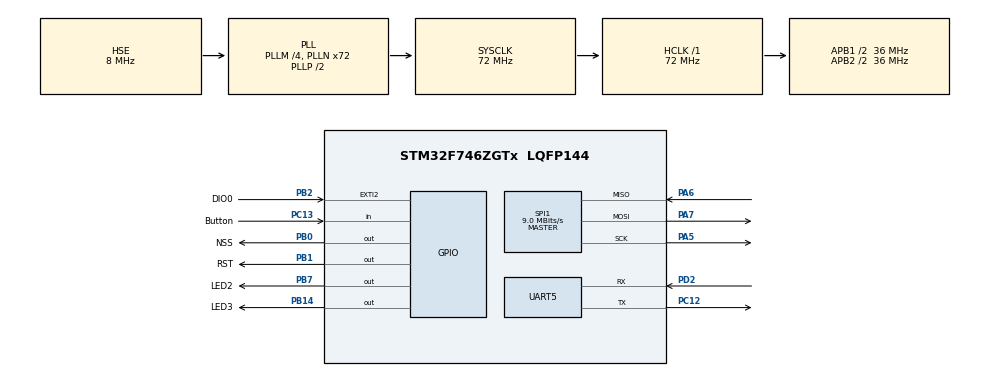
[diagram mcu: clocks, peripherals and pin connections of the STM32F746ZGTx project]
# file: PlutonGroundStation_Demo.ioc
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Mcu.Family=STM32F7
Mcu.Name=STM32F746ZGTx
Mcu.Package=LQFP144
NVIC.EXTI2_IRQn=true\:1\:1\:true\:false\:true\:true\:true\:true
NVIC.PriorityGroup=NVIC_PRIORITYGROUP_2
NVIC.UART5_IRQn=true\:1\:0\:true\:false\:true\:true\:true\:true
PA13.Mode=Serial_Wire
PA13.Signal=SYS_JTMS-SWDIO
PA14.Mode=Serial_Wire
PA14.Signal=SYS_JTCK-SWCLK
PA5.Mode=Full_Duplex_Master
PA5.Signal=SPI1_SCK
PA6.Mode=Full_Duplex_Master
PA6.Signal=SPI1_MISO
PA7.Mode=Full_Duplex_Master
PA7.Signal=SPI1_MOSI
PB0.GPIO_Label=NSS
PB0.PinState=GPIO_PIN_SET
PB0.Signal=GPIO_Output
PB1.GPIO_Label=RST
PB1.PinState=GPIO_PIN_SET
PB1.Signal=GPIO_Output
PB14.GPIO_Label=LED3
PB14.Signal=GPIO_Output
PB2.GPIO_Label=DIO0
PB2.Signal=GPXTI2
PB7.GPIO_Label=LED2
PB7.Signal=GPIO_Output
PC12.Mode=Asynchronous
PC12.Signal=UART5_TX
PC13.GPIO_Label=Button
PC13.Signal=GPIO_Input
PD2.Mode=Asynchronous
PD2.Signal=UART5_RX
PH0/OSC_IN.Mode=HSE-External-Oscillator
PH0/OSC_IN.Signal=RCC_OSC_IN
PH1/OSC_OUT.Mode=HSE-External-Oscillator
PH1/OSC_OUT.Signal=RCC_OSC_OUT
ProjectManager.HeapSize=0x200
ProjectManager.StackSize=0x400
ProjectManager.TargetToolchain=STM32CubeIDE
RCC.AHBFreq_Value=72000000
RCC.APB1CLKDivider=RCC_HCLK_DIV2
RCC.APB1Freq_Value=36000000
RCC.APB1TimFreq_Value=72000000
RCC.APB2CLKDivider=RCC_HCLK_DIV2
RCC.APB2Freq_Value=36000000
RCC.APB2TimFreq_Value=72000000
RCC.CortexFreq_Value=72000000
RCC.HCLKFreq_Value=72000000
RCC.HSE_VALUE=8000000
RCC.HSI_VALUE=16000000
RCC.LSE_VALUE=32768
RCC.PLLM=4
RCC.PLLN=72
RCC.PLLSourceVirtual=RCC_PLLSOURCE_HSE
RCC.SYSCLKFreq_VALUE=72000000
RCC.SYSCLKSource=RCC_SYSCLKSOURCE_PLLCLK
RCC.USBFreq_Value=72000000
RCC.VCOOutputFreq_Value=144000000
SPI1.BaudRatePrescaler=SPI_BAUDRATEPRESCALER_4
SPI1.CalculateBaudRate=9.0 MBits/s
SPI1.DataSize=SPI_DATASIZE_8BIT
SPI1.Direction=SPI_DIRECTION_2LINES
SPI1.Mode=SPI_MODE_MASTER
SPI1.VirtualType=VM_MASTER
board=custom

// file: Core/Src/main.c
/* USER CODE BEGIN Header */
/**
 ******************************************************************************
 * @file           : main.c
 * @brief          : Main program body
 ******************************************************************************
 * @attention
 *
 * Copyright (c) 2023 STMicroelectronics.
 * All rights reserved.
 *
 * This software is licensed under terms that can be found in the LICENSE file
 * in the root directory of this software component.
 * If no LICENSE file comes with this software, it is provided AS-IS.
 *
 ******************************************************************************
 */
/* USER CODE END Header */
#include "main.h"
#include "spi.h"
#include "usart.h"
#include "gpio.h"

/* USER CODE BEGIN Includes */
//#include "Main_App.h"
/* USER CODE END Includes */

void SystemClock_Config(void);

/* USER CODE BEGIN 0 */
void delay_ms(uint32_t ms) {
	uint32_t start = HAL_GetTick(); // Obtiene el tiempo inicial
	while ((HAL_GetTick() - start) < ms);
}
/* USER CODE END 0 */

int main(void)
{

  /* MCU Configuration--------------------------------------------------------*/

  /* Reset of all peripherals, Initializes the Flash interface and the Systick. */
  HAL_Init();

  /* Configure the system clock */
  SystemClock_Config();

  /* Initialize all configured peripherals */
  MX_GPIO_Init();
  MX_UART5_Init();
  MX_SPI1_Init();
  /* USER CODE BEGIN 2 */

	//------------MAIN APP INIT-----------------
	LoraApp_init();
	//------------------------------------------

  /* USER CODE END 2 */

  /* Infinite loop */
  /* USER CODE BEGIN WHILE */
	while (1)
	{
		//------------MAIN APP LOOP-----------------
		LoraApp_loopReceive();
		//------------------------------------------
    /* USER CODE END WHILE */

	}
}

void SystemClock_Config(void)
{
  RCC_OscInitTypeDef RCC_OscInitStruct = {0};
  RCC_ClkInitTypeDef RCC_ClkInitStruct = {0};

  /** Configure the main internal regulator output voltage
  */
  __HAL_RCC_PWR_CLK_ENABLE();
  __HAL_PWR_VOLTAGESCALING_CONFIG(PWR_REGULATOR_VOLTAGE_SCALE3);

  /** Initializes the RCC Oscillators according to the specified parameters
  * in the RCC_OscInitTypeDef structure.
  */
  RCC_OscInitStruct.OscillatorType = RCC_OSCILLATORTYPE_HSE;
  RCC_OscInitStruct.HSEState = RCC_HSE_ON;
  RCC_OscInitStruct.PLL.PLLState = RCC_PLL_ON;
  RCC_OscInitStruct.PLL.PLLSource = RCC_PLLSOURCE_HSE;
  RCC_OscInitStruct.PLL.PLLM = 4;
  RCC_OscInitStruct.PLL.PLLN = 72;
  RCC_OscInitStruct.PLL.PLLP = RCC_PLLP_DIV2;
  RCC_OscInitStruct.PLL.PLLQ = 2;
  if (HAL_RCC_OscConfig(&RCC_OscInitStruct) != HAL_OK)
  {
    Error_Handler();
  }

  /** Initializes the CPU, AHB and APB buses clocks
  */
  RCC_ClkInitStruct.ClockType = RCC_CLOCKTYPE_HCLK|RCC_CLOCKTYPE_SYSCLK
                              |RCC_CLOCKTYPE_PCLK1|RCC_CLOCKTYPE_PCLK2;
  RCC_ClkInitStruct.SYSCLKSource = RCC_SYSCLKSOURCE_PLLCLK;
  RCC_ClkInitStruct.AHBCLKDivider = RCC_SYSCLK_DIV1;
  RCC_ClkInitStruct.APB1CLKDivider = RCC_HCLK_DIV2;
  RCC_ClkInitStruct.APB2CLKDivider = RCC_HCLK_DIV2;

  if (HAL_RCC_ClockConfig(&RCC_ClkInitStruct, FLASH_LATENCY_2) != HAL_OK)
  {
    Error_Handler();
  }
}

/* USER CODE BEGIN 4 */
//---------------------UART INTERRUPTION----------------------------------
void HAL_UART_RxCpltCallback(UART_HandleTypeDef *huart) {
	if (huart == &huart5) {
		LoraApp_loopSerial();
		delay_ms(1000);
	}
}
//------------------------------------------------------------------------
//---------------------DIO0 INTERRUPTION----------------------------------
void HAL_GPIO_EXTI_Callback(uint16_t GPIO_Pin){
	if(GPIO_Pin == DIO0_Pin){
		//Se ha producido una interupcion en la recepcion
		onInterrupt();
	}
}
//------------------------------------------------------------------------
/* USER CODE END 4 */

void Error_Handler(void)
{
	__disable_irq();
	while (1)
	{
	}
}
